VERSION ""

NS_ :

BS_:

BU_: LV_BOX

BO_ 1680 LV_BOX_ANALOG: 3 LV_BOX
 SG_ TODO_TEMP_1 : 0|12@1+ (0.0008058608058608059,0) [0|3.3] "V" Vector__XXX
 SG_ TODO_TEMP_2 : 12|12@1+ (0.0008058608058608059,0) [0|3.3] "V" Vector__XXX

BO_ 1685 LV_BOX_DIGITAL: 1 LV_BOX
 SG_ TODO_IN_1 : 0|1@1+ (1,0) [0|1] "bool" Vector__XXX

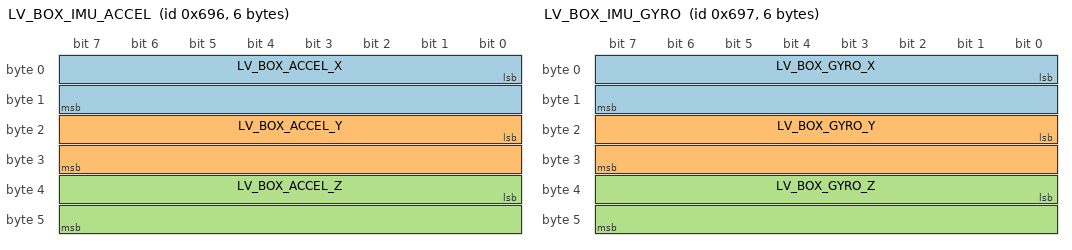
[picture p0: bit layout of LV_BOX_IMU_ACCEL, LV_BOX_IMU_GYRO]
BO_ 1686 LV_BOX_IMU_ACCEL: 6 LV_BOX
 SG_ LV_BOX_ACCEL_X : 0|16@1- (0.000122,0) [-4|4] "g" Vector__XXX
 SG_ LV_BOX_ACCEL_Y : 16|16@1- (0.000122,0) [-4|4] "g" Vector__XXX
 SG_ LV_BOX_ACCEL_Z : 32|16@1- (0.000122,0) [-4|4] "g" Vector__XXX

BO_ 1687 LV_BOX_IMU_GYRO: 6 LV_BOX
 SG_ LV_BOX_GYRO_X : 0|16@1- (0.0175,0) [-500|500] "dps" Vector__XXX
 SG_ LV_BOX_GYRO_Y : 16|16@1- (0.0175,0) [-500|500] "dps" Vector__XXX
 SG_ LV_BOX_GYRO_Z : 32|16@1- (0.0175,0) [-500|500] "dps" Vector__XXX

BO_ 1688 LV_BOX_TEMP: 4 LV_BOX
 SG_ LV_BOX_IMU_TEMP : 0|16@1- (0.00390625,25) [-40|85] "degC" Vector__XXX
 SG_ LV_BOX_AMBIENT_TEMP : 16|16@1- (0.0625,0) [-55|125] "degC" Vector__XXX

BO_ 1689 LV_BOX_STATUS: 1 LV_BOX
 SG_ LV_BOX_ISM330_OK : 0|1@1+ (1,0) [0|1] "" Vector__XXX
 SG_ LV_BOX_MCP9800_OK : 1|1@1+ (1,0) [0|1] "" Vector__XXX
